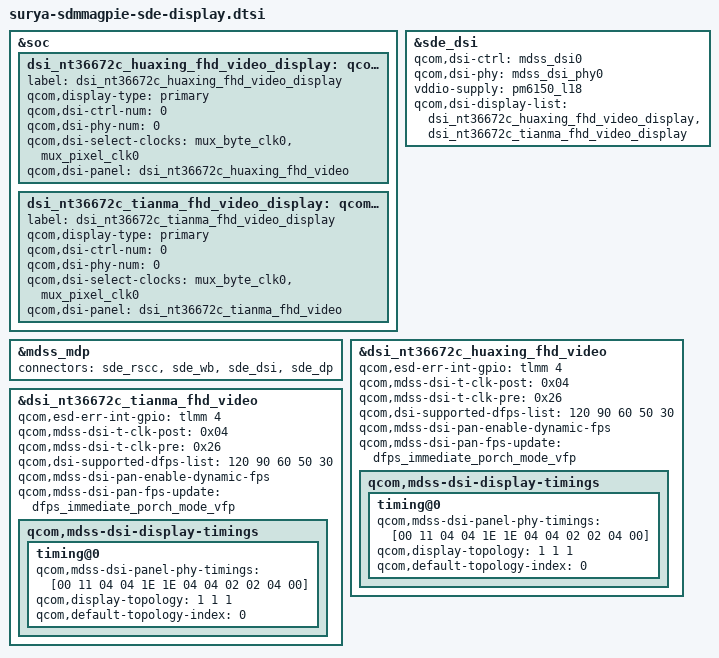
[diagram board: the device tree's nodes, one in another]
#include "dsi-panel-nt36672c-huaxing-fhd-video.dtsi"
#include "dsi-panel-nt36672c-tianma-fhd-video.dtsi"

&soc {
	dsi_nt36672c_huaxing_fhd_video_display: qcom,dsi-display@22 {
		label = "dsi_nt36672c_huaxing_fhd_video_display";
		qcom,display-type = "primary";
		qcom,dsi-ctrl-num = <0>;
		qcom,dsi-phy-num = <0>;
		qcom,dsi-select-clocks = "mux_byte_clk0", "mux_pixel_clk0";

		qcom,dsi-panel = <&dsi_nt36672c_huaxing_fhd_video>;
	};

	dsi_nt36672c_tianma_fhd_video_display: qcom,dsi-display@23 {
		label = "dsi_nt36672c_tianma_fhd_video_display";
		qcom,display-type = "primary";
		qcom,dsi-ctrl-num = <0>;
		qcom,dsi-phy-num = <0>;
		qcom,dsi-select-clocks = "mux_byte_clk0", "mux_pixel_clk0";

		qcom,dsi-panel = <&dsi_nt36672c_tianma_fhd_video>;
	};
};

&sde_dsi {
	/delete-property/ vdda-3p3-supply;

	qcom,dsi-ctrl = <&mdss_dsi0>;
	qcom,dsi-phy = <&mdss_dsi_phy0>;

	vddio-supply = <&pm6150_l18>;

	qcom,dsi-display-list =
		<&dsi_nt36672c_huaxing_fhd_video_display
		&dsi_nt36672c_tianma_fhd_video_display>;
};

&mdss_mdp {
	connectors = <&sde_rscc &sde_wb &sde_dsi &sde_dp>;
};

&dsi_nt36672c_huaxing_fhd_video {
	qcom,esd-err-int-gpio = <&tlmm 4 0>;
	qcom,mdss-dsi-t-clk-post = <0x04>;
	qcom,mdss-dsi-t-clk-pre = <0x26>;
	qcom,dsi-supported-dfps-list = <120 90 60 50 30>;
	qcom,mdss-dsi-pan-enable-dynamic-fps;
	qcom,mdss-dsi-pan-fps-update = "dfps_immediate_porch_mode_vfp";
	qcom,mdss-dsi-display-timings {
		timing@0{
			qcom,mdss-dsi-panel-phy-timings =[00 11 04 04 1E 1E 04
				 04 02 02 04 00];
			qcom,display-topology = <1 1 1>;
			qcom,default-topology-index = <0>;
		};
	};
};

&dsi_nt36672c_tianma_fhd_video {
	qcom,esd-err-int-gpio = <&tlmm 4 0>;
	qcom,mdss-dsi-t-clk-post = <0x04>;
	qcom,mdss-dsi-t-clk-pre = <0x26>;
	qcom,dsi-supported-dfps-list = <120 90 60 50 30>;
	qcom,mdss-dsi-pan-enable-dynamic-fps;
	qcom,mdss-dsi-pan-fps-update = "dfps_immediate_porch_mode_vfp";
	qcom,mdss-dsi-display-timings {
		timing@0{
			qcom,mdss-dsi-panel-phy-timings =[00 11 04 04 1E 1E 04
				 04 02 02 04 00];
			qcom,display-topology = <1 1 1>;
			qcom,default-topology-index = <0>;
		};
	};
};
